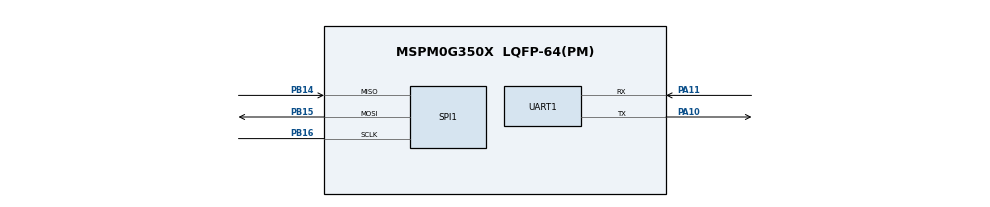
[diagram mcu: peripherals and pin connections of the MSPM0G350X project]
/**
 * @cliArgs --device "MSPM0G350X" --part "Default" --package "LQFP-64(PM)" --product "mspm0_sdk@2.02.00.05"
 * @versions {"tool":"1.21.1+3772"}
 */

/**
 * Import the modules used in this configuration.
 */
const GPIO    = scripting.addModule("/ti/driverlib/GPIO", {}, false);
const GPIO1   = GPIO.addInstance();
const GPIO2   = GPIO.addInstance();
const GPIO3   = GPIO.addInstance();
const GPIO4   = GPIO.addInstance();
const GPIO5   = GPIO.addInstance();
const GPIO6   = GPIO.addInstance();
const GPIO7   = GPIO.addInstance();
const SPI     = scripting.addModule("/ti/driverlib/SPI", {}, false);
const SPI1    = SPI.addInstance();
const SYSCTL  = scripting.addModule("/ti/driverlib/SYSCTL");
const SYSTICK = scripting.addModule("/ti/driverlib/SYSTICK");
const UART    = scripting.addModule("/ti/driverlib/UART", {}, false);
const UART1   = UART.addInstance();

/**
 * Write custom configuration values to the imported modules.
 */
const gate7  = system.clockTree["MFCLKGATE"];
gate7.enable = true;

GPIO1.$name                          = "BLK";
GPIO1.port                           = "PORTB";
GPIO1.associatedPins[0].$name        = "PIN_19";
GPIO1.associatedPins[0].initialValue = "SET";
GPIO1.associatedPins[0].assignedPin  = "19";

const Board = scripting.addModule("/ti/driverlib/Board", {}, false);

GPIO2.$name                         = "CS";
GPIO2.port                          = "PORTA";
GPIO2.associatedPins[0].$name       = "PIN_23";
GPIO2.associatedPins[0].assignedPin = "23";

GPIO3.$name                         = "DC";
GPIO3.port                          = "PORTB";
GPIO3.associatedPins[0].$name       = "PIN_24";
GPIO3.associatedPins[0].assignedPin = "24";

GPIO4.$name                         = "RES";
GPIO4.port                          = "PORTB";
GPIO4.associatedPins[0].$name       = "PIN_20";
GPIO4.associatedPins[0].assignedPin = "20";

GPIO5.$name                         = "MOSI";
GPIO5.port                          = "PORTA";
GPIO5.associatedPins[0].$name       = "PIN_28";
GPIO5.associatedPins[0].assignedPin = "28";

GPIO6.$name                         = "SCLK";
GPIO6.port                          = "PORTA";
GPIO6.associatedPins[0].$name       = "PIN_31";
GPIO6.associatedPins[0].assignedPin = "31";

GPIO7.$name                          = "CS1";
GPIO7.associatedPins[0].$name        = "PIN_17";
GPIO7.associatedPins[0].assignedPort = "PORTB";
GPIO7.associatedPins[0].assignedPin  = "17";

SPI1.$name                              = "SPI";
SPI1.targetBitRate                      = 16000000;
SPI1.frameFormat                        = "MOTO3";
SPI1.peripheral.$assign                 = "SPI1";
SPI1.peripheral.sclkPin.$assign         = "PB16";
SPI1.peripheral.mosiPin.$assign         = "PB15";
SPI1.peripheral.misoPin.$assign         = "PB14";
SPI1.sclkPinConfig.$name                = "ti_driverlib_gpio_GPIOPinGeneric2";
SPI1.sclkPinConfig.direction            = scripting.forceWrite("OUTPUT");
SPI1.sclkPinConfig.onlyInternalResistor = scripting.forceWrite(false);
SPI1.sclkPinConfig.passedPeripheralType = scripting.forceWrite("Digital");
SPI1.mosiPinConfig.$name                = "ti_driverlib_gpio_GPIOPinGeneric3";
SPI1.mosiPinConfig.direction            = scripting.forceWrite("OUTPUT");
SPI1.mosiPinConfig.hideOutputInversion  = scripting.forceWrite(false);
SPI1.mosiPinConfig.onlyInternalResistor = scripting.forceWrite(false);
SPI1.mosiPinConfig.passedPeripheralType = scripting.forceWrite("Digital");
SPI1.misoPinConfig.$name                = "ti_driverlib_gpio_GPIOPinGeneric4";
SPI1.misoPinConfig.onlyInternalResistor = scripting.forceWrite(false);
SPI1.misoPinConfig.passedPeripheralType = scripting.forceWrite("Digital");

SYSCTL.forceDefaultClkConfig = true;
SYSCTL.clockTreeEn           = true;

SYSTICK.periodEnable      = true;
SYSTICK.interruptPriority = "0";
SYSTICK.systickEnable     = true;
SYSTICK.period            = 32;

UART1.$name                    = "UART_0";
UART1.uartClkSrc               = "MFCLK";
UART1.enabledInterrupts        = ["RX"];
UART1.peripheral.rxPin.$assign = "PA11";
UART1.peripheral.txPin.$assign = "PA10";
UART1.txPinConfig.$name        = "ti_driverlib_gpio_GPIOPinGeneric0";
UART1.rxPinConfig.$name        = "ti_driverlib_gpio_GPIOPinGeneric1";

/**
 * Pinmux solution for unlocked pins/peripherals. This ensures that minor changes to the automatic solver in a future
 * version of the tool will not impact the pinmux you originally saw.  These lines can be completely deleted in order to
 * re-solve from scratch.
 */
GPIO1.associatedPins[0].pin.$suggestSolution = "PB19";
Board.peripheral.$suggestSolution            = "DEBUGSS";
Board.peripheral.swclkPin.$suggestSolution   = "PA20";
Board.peripheral.swdioPin.$suggestSolution   = "PA19";
GPIO2.associatedPins[0].pin.$suggestSolution = "PA23";
GPIO3.associatedPins[0].pin.$suggestSolution = "PB24";
GPIO4.associatedPins[0].pin.$suggestSolution = "PB20";
GPIO5.associatedPins[0].pin.$suggestSolution = "PA28";
GPIO6.associatedPins[0].pin.$suggestSolution = "PA31";
GPIO7.associatedPins[0].pin.$suggestSolution = "PB17";
UART1.peripheral.$suggestSolution            = "UART0";
